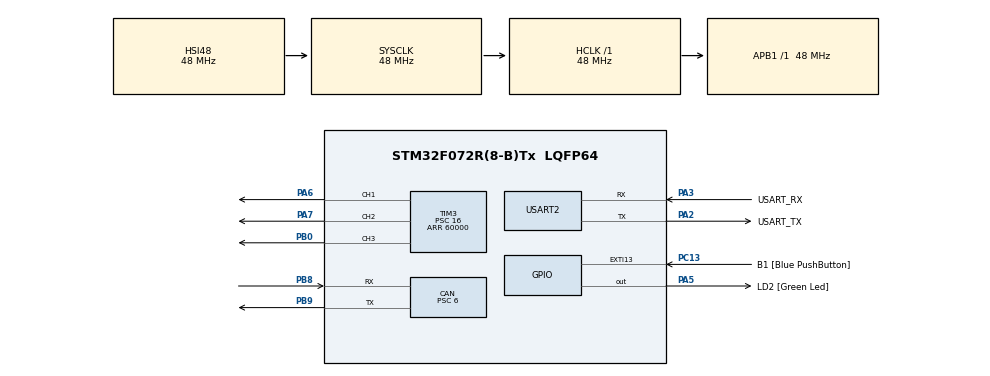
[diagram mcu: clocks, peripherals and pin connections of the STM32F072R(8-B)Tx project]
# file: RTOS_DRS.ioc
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CAN.ABOM=ENABLE
CAN.AWUM=ENABLE
CAN.BS1=CAN_BS1_6TQ
CAN.BS2=CAN_BS2_1TQ
CAN.CalculateTimeQuantum=125.0
CAN.Prescaler=6
FREERTOS.Tasks01=start_update_ca,24,128,start_update_calculate_wing_angle,Default,NULL,Dynamic,NULL,NULL;actuate_wings,24,128,start_actuate_wings,Default,NULL,Dynamic,NULL,NULL;DRS_button,24,128,start_DRS_button,Default,NULL,Dynamic,NULL,NULL;start_fetch_dat,24,128,start_fetch_data,Default,NULL,Dynamic,NULL,NULL
Mcu.Family=STM32F0
Mcu.Name=STM32F072R(8-B)Tx
Mcu.Package=LQFP64
NVIC.CEC_CAN_IRQn=true\:0\:0\:false\:false\:true\:true\:true\:true
NVIC.TIM6_DAC_IRQn=true\:0\:0\:false\:false\:true\:false\:false\:true
NVIC.TimeBase=TIM6_DAC_IRQn
NVIC.TimeBaseIP=TIM6
PA13.GPIO_Label=TMS
PA13.Mode=Serial_Wire
PA13.Signal=SYS_SWDIO
PA14.GPIO_Label=TCK
PA14.Mode=Serial_Wire
PA14.Signal=SYS_SWCLK
PA2.GPIO_Label=USART_TX
PA2.GPIO_Mode=GPIO_MODE_AF_PP
PA2.GPIO_PuPd=GPIO_NOPULL
PA2.GPIO_Speed=GPIO_SPEED_FREQ_LOW
PA2.Mode=Asynchronous
PA2.Signal=USART2_TX
PA3.GPIO_Label=USART_RX
PA3.GPIO_Mode=GPIO_MODE_AF_PP
PA3.GPIO_PuPd=GPIO_NOPULL
PA3.GPIO_Speed=GPIO_SPEED_FREQ_LOW
PA3.Mode=Asynchronous
PA3.Signal=USART2_RX
PA5.GPIO_Label=LD2 [Green Led]
PA5.GPIO_Mode=GPIO_MODE_OUTPUT_PP
PA5.GPIO_PuPd=GPIO_NOPULL
PA5.GPIO_Speed=GPIO_SPEED_FREQ_LOW
PA5.Signal=GPIO_Output
PA6.Signal=S_TIM3_CH1
PA7.Signal=S_TIM3_CH2
PB0.Signal=S_TIM3_CH3
PB8.Mode=Master
PB8.Signal=CAN_RX
PB9.Mode=Master
PB9.Signal=CAN_TX
PC13.GPIO_Label=B1 [Blue PushButton]
PC13.GPIO_ModeDefaultEXTI=GPIO_MODE_IT_FALLING
PC13.Signal=GPXTI13
PC14-OSC32_IN.Mode=LSE-External-Oscillator
PC14-OSC32_IN.Signal=RCC_OSC32_IN
PC15-OSC32_OUT.Mode=LSE-External-Oscillator
PC15-OSC32_OUT.Signal=RCC_OSC32_OUT
PF0-OSC_IN.Mode=HSE-External-Oscillator
PF0-OSC_IN.Signal=RCC_OSC_IN
PF1-OSC_OUT.Mode=HSE-External-Oscillator
PF1-OSC_OUT.Signal=RCC_OSC_OUT
ProjectManager.HeapSize=0x200
ProjectManager.StackSize=0x400
ProjectManager.TargetToolchain=STM32CubeIDE
RCC.AHBFreq_Value=48000000
RCC.APB1Freq_Value=48000000
RCC.APB1TimFreq_Value=48000000
RCC.FLatency-AdvancedSettings=FLASH_LATENCY_1
RCC.HCLKFreq_Value=48000000
RCC.PLLDivider=RCC_PREDIV_DIV2
RCC.PLLMUL=RCC_PLL_MUL12
RCC.PREFETCH_ENABLE-AdvancedSettings=1
RCC.SYSCLKFreq_VALUE=48000000
RCC.SYSCLKSource=RCC_SYSCLKSOURCE_HSI48
SH.S_TIM3_CH1.0=TIM3_CH1,PWM Generation1 CH1
SH.S_TIM3_CH2.0=TIM3_CH2,PWM Generation2 CH2
SH.S_TIM3_CH3.0=TIM3_CH3,PWM Generation3 CH3
TIM14.Prescaler=183
TIM3.Channel-PWM\ Generation1\ CH1=TIM_CHANNEL_1
TIM3.Channel-PWM\ Generation2\ CH2=TIM_CHANNEL_2
TIM3.Channel-PWM\ Generation3\ CH3=TIM_CHANNEL_3
TIM3.Period=60000
TIM3.Prescaler=16
USART2.VirtualMode=VM_ASYNC
USART2.VirtualMode-Asynchronous=VM_ASYNC
VP_FREERTOS_VS_CMSIS_V2.Mode=CMSIS_V2
VP_SYS_VS_tim6.Mode=TIM6
VP_TIM14_VS_ClockSourceINT.Mode=Enable_Timer
board=NUCLEO-F072RB

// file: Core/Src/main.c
/* USER CODE BEGIN Header */
/**
  ******************************************************************************
  * @file           : main.c
  * @brief          : Main program body
  ******************************************************************************
  * @attention
  *
  * <h2><center>&copy; Copyright (c) 2020 STMicroelectronics.
  * All rights reserved.</center></h2>
  *
  * This software component is licensed by ST under BSD 3-Clause license,
  * the "License"; You may not use this file except in compliance with the
  * License. You may obtain a copy of the License at:
  *                        opensource.org/licenses/BSD-3-Clause
  *
  ******************************************************************************
  */
/* USER CODE END Header */
#include "main.h"
#include "cmsis_os.h"

/* USER CODE BEGIN Includes */
#include "GO4_ACM_2020.h"
/* USER CODE END Includes */

CAN_HandleTypeDef hcan;

TIM_HandleTypeDef htim3;
TIM_HandleTypeDef htim14;

UART_HandleTypeDef huart2;

/* Definitions for start_update_ca */
osThreadId_t start_update_caHandle;
const osThreadAttr_t start_update_ca_attributes = {
  .name = "start_update_ca",
  .priority = (osPriority_t) osPriorityNormal,
  .stack_size = 128 * 4
};
/* Definitions for actuate_wings */
osThreadId_t actuate_wingsHandle;
const osThreadAttr_t actuate_wings_attributes = {
  .name = "actuate_wings",
  .priority = (osPriority_t) osPriorityNormal,
  .stack_size = 128 * 4
};
/* Definitions for DRS_button */
osThreadId_t DRS_buttonHandle;
const osThreadAttr_t DRS_button_attributes = {
  .name = "DRS_button",
  .priority = (osPriority_t) osPriorityNormal,
  .stack_size = 128 * 4
};
/* Definitions for start_fetch_dat */
osThreadId_t start_fetch_datHandle;
const osThreadAttr_t start_fetch_dat_attributes = {
  .name = "start_fetch_dat",
  .priority = (osPriority_t) osPriorityNormal,
  .stack_size = 128 * 4
};

void SystemClock_Config(void);
static void MX_GPIO_Init(void);
static void MX_USART2_UART_Init(void);
static void MX_TIM3_Init(void);
static void MX_CAN_Init(void);
static void MX_TIM14_Init(void);
void start_update_calculate_wing_angle(void *argument);
void start_actuate_wings(void *argument);
void start_DRS_button(void *argument);
void start_fetch_data(void *argument);

int main(void)
{

  /* MCU Configuration--------------------------------------------------------*/

  /* Reset of all peripherals, Initializes the Flash interface and the Systick. */
  HAL_Init();

  /* Configure the system clock */
  SystemClock_Config();

  /* Initialize all configured peripherals */
  MX_GPIO_Init();
  MX_USART2_UART_Init();
  MX_TIM3_Init();
  MX_CAN_Init();
  MX_TIM14_Init();
  /* USER CODE BEGIN 2 */
  /************** RUNNING CONFIG CALLS **************/

  ACM_Init();

  /* USER CODE END 2 */

  /* Init scheduler */
  osKernelInitialize();

  /* Create the thread(s) */
  /* creation of start_update_ca */
  start_update_caHandle = osThreadNew(start_update_calculate_wing_angle, NULL, &start_update_ca_attributes);

  /* creation of actuate_wings */
  actuate_wingsHandle = osThreadNew(start_actuate_wings, NULL, &actuate_wings_attributes);

  /* creation of DRS_button */
  DRS_buttonHandle = osThreadNew(start_DRS_button, NULL, &DRS_button_attributes);

  /* creation of start_fetch_dat */
  start_fetch_datHandle = osThreadNew(start_fetch_data, NULL, &start_fetch_dat_attributes);

  /* Start scheduler */
  osKernelStart();

  /* We should never get here as control is now taken by the scheduler */
  /* Infinite loop */
  while (1)
  {

  }
}

void SystemClock_Config(void)
{
  RCC_OscInitTypeDef RCC_OscInitStruct = {0};
  RCC_ClkInitTypeDef RCC_ClkInitStruct = {0};
  RCC_PeriphCLKInitTypeDef PeriphClkInit = {0};

  /** Initializes the RCC Oscillators according to the specified parameters
  * in the RCC_OscInitTypeDef structure.
  */
  RCC_OscInitStruct.OscillatorType = RCC_OSCILLATORTYPE_HSI48;
  RCC_OscInitStruct.HSI48State = RCC_HSI48_ON;
  RCC_OscInitStruct.PLL.PLLState = RCC_PLL_NONE;
  if (HAL_RCC_OscConfig(&RCC_OscInitStruct) != HAL_OK)
  {
    Error_Handler();
  }
  /** Initializes the CPU, AHB and APB buses clocks
  */
  RCC_ClkInitStruct.ClockType = RCC_CLOCKTYPE_HCLK|RCC_CLOCKTYPE_SYSCLK
                              |RCC_CLOCKTYPE_PCLK1;
  RCC_ClkInitStruct.SYSCLKSource = RCC_SYSCLKSOURCE_HSI48;
  RCC_ClkInitStruct.AHBCLKDivider = RCC_SYSCLK_DIV1;
  RCC_ClkInitStruct.APB1CLKDivider = RCC_HCLK_DIV1;

  if (HAL_RCC_ClockConfig(&RCC_ClkInitStruct, FLASH_LATENCY_1) != HAL_OK)
  {
    Error_Handler();
  }
  PeriphClkInit.PeriphClockSelection = RCC_PERIPHCLK_USART2;
  PeriphClkInit.Usart2ClockSelection = RCC_USART2CLKSOURCE_PCLK1;
  if (HAL_RCCEx_PeriphCLKConfig(&PeriphClkInit) != HAL_OK)
  {
    Error_Handler();
  }
}

static void MX_CAN_Init(void)
{

  hcan.Instance = CAN;
  hcan.Init.Prescaler = 6;
  hcan.Init.Mode = CAN_MODE_NORMAL;
  hcan.Init.SyncJumpWidth = CAN_SJW_1TQ;
  hcan.Init.TimeSeg1 = CAN_BS1_6TQ;
  hcan.Init.TimeSeg2 = CAN_BS2_1TQ;
  hcan.Init.TimeTriggeredMode = DISABLE;
  hcan.Init.AutoBusOff = ENABLE;
  hcan.Init.AutoWakeUp = ENABLE;
  hcan.Init.AutoRetransmission = DISABLE;
  hcan.Init.ReceiveFifoLocked = DISABLE;
  hcan.Init.TransmitFifoPriority = DISABLE;
  if (HAL_CAN_Init(&hcan) != HAL_OK)
  {
    Error_Handler();
  }

}

static void MX_TIM3_Init(void)
{

  TIM_MasterConfigTypeDef sMasterConfig = {0};
  TIM_OC_InitTypeDef sConfigOC = {0};

  htim3.Instance = TIM3;
  htim3.Init.Prescaler = 16;
  htim3.Init.CounterMode = TIM_COUNTERMODE_UP;
  htim3.Init.Period = 60000;
  htim3.Init.ClockDivision = TIM_CLOCKDIVISION_DIV1;
  htim3.Init.AutoReloadPreload = TIM_AUTORELOAD_PRELOAD_DISABLE;
  if (HAL_TIM_PWM_Init(&htim3) != HAL_OK)
  {
    Error_Handler();
  }
  sMasterConfig.MasterOutputTrigger = TIM_TRGO_RESET;
  sMasterConfig.MasterSlaveMode = TIM_MASTERSLAVEMODE_DISABLE;
  if (HAL_TIMEx_MasterConfigSynchronization(&htim3, &sMasterConfig) != HAL_OK)
  {
    Error_Handler();
  }
  sConfigOC.OCMode = TIM_OCMODE_PWM1;
  sConfigOC.Pulse = 0;
  sConfigOC.OCPolarity = TIM_OCPOLARITY_HIGH;
  sConfigOC.OCFastMode = TIM_OCFAST_DISABLE;
  if (HAL_TIM_PWM_ConfigChannel(&htim3, &sConfigOC, TIM_CHANNEL_1) != HAL_OK)
  {
    Error_Handler();
  }
  if (HAL_TIM_PWM_ConfigChannel(&htim3, &sConfigOC, TIM_CHANNEL_2) != HAL_OK)
  {
    Error_Handler();
  }
  if (HAL_TIM_PWM_ConfigChannel(&htim3, &sConfigOC, TIM_CHANNEL_3) != HAL_OK)
  {
    Error_Handler();
  }
  HAL_TIM_MspPostInit(&htim3);

}

static void MX_TIM14_Init(void)
{

  htim14.Instance = TIM14;
  htim14.Init.Prescaler = 183;
  htim14.Init.CounterMode = TIM_COUNTERMODE_UP;
  htim14.Init.Period = 65535;
  htim14.Init.ClockDivision = TIM_CLOCKDIVISION_DIV1;
  htim14.Init.AutoReloadPreload = TIM_AUTORELOAD_PRELOAD_DISABLE;
  if (HAL_TIM_Base_Init(&htim14) != HAL_OK)
  {
    Error_Handler();
  }

}

static void MX_USART2_UART_Init(void)
{

  huart2.Instance = USART2;
  huart2.Init.BaudRate = 38400;
  huart2.Init.WordLength = UART_WORDLENGTH_8B;
  huart2.Init.StopBits = UART_STOPBITS_1;
  huart2.Init.Parity = UART_PARITY_NONE;
  huart2.Init.Mode = UART_MODE_TX_RX;
  huart2.Init.HwFlowCtl = UART_HWCONTROL_NONE;
  huart2.Init.OverSampling = UART_OVERSAMPLING_16;
  huart2.Init.OneBitSampling = UART_ONE_BIT_SAMPLE_DISABLE;
  huart2.AdvancedInit.AdvFeatureInit = UART_ADVFEATURE_NO_INIT;
  if (HAL_UART_Init(&huart2) != HAL_OK)
  {
    Error_Handler();
  }

}

static void MX_GPIO_Init(void)
{
  GPIO_InitTypeDef GPIO_InitStruct = {0};

  /* GPIO Ports Clock Enable */
  __HAL_RCC_GPIOC_CLK_ENABLE();
  __HAL_RCC_GPIOF_CLK_ENABLE();
  __HAL_RCC_GPIOA_CLK_ENABLE();
  __HAL_RCC_GPIOB_CLK_ENABLE();

  /*Configure GPIO pin Output Level */
  HAL_GPIO_WritePin(LD2_GPIO_Port, LD2_Pin, GPIO_PIN_RESET);

  /*Configure GPIO pin : B1_Pin */
  GPIO_InitStruct.Pin = B1_Pin;
  GPIO_InitStruct.Mode = GPIO_MODE_IT_FALLING;
  GPIO_InitStruct.Pull = GPIO_NOPULL;
  HAL_GPIO_Init(B1_GPIO_Port, &GPIO_InitStruct);

  /*Configure GPIO pin : LD2_Pin */
  GPIO_InitStruct.Pin = LD2_Pin;
  GPIO_InitStruct.Mode = GPIO_MODE_OUTPUT_PP;
  GPIO_InitStruct.Pull = GPIO_NOPULL;
  GPIO_InitStruct.Speed = GPIO_SPEED_FREQ_LOW;
  HAL_GPIO_Init(LD2_GPIO_Port, &GPIO_InitStruct);

}

void start_update_calculate_wing_angle(void *argument)
{
  /* USER CODE BEGIN 5 */
  /* Infinite loop */
  for(;;)
  {
	  //update the data
	  update_data();

	  //Pick all of the necessary values that should be used for calculation
	  arbitrate_acceleration();
	  arbitrate_speed();
	  arbitrate_steering_angle();

	  calculate_wing_angle();

	  osDelay(1);
  }
  // In case something gets severely whacked
    osThreadTerminate(NULL);

  /* USER CODE END 5 */
}

void start_actuate_wings(void *argument)
{
  /* USER CODE BEGIN start_actuate_wings */
  /* Infinite loop */
  for(;;)
  {
	  // send information to the servos
	  output_angles();
	  osDelay(1);
  }
  /* USER CODE END start_actuate_wings */
}

void start_DRS_button(void *argument)
{
  /* USER CODE BEGIN start_DRS_button */
  /* Infinite loop */
  for(;;)
  {
	  get_btn_state();
	  osDelay(1);
  }
  /* USER CODE END start_DRS_button */
}

void start_fetch_data(void *argument)
{
  /* USER CODE BEGIN start_fetch_data */
  /* Infinite loop */
  for(;;)
  {
	  // Send for all data without interfering with calculations
	  fetch_data();

	  osDelay(1);
  }
  /* USER CODE END start_fetch_data */
}

void HAL_TIM_PeriodElapsedCallback(TIM_HandleTypeDef *htim)
{
  if (htim->Instance == TIM6) {
    HAL_IncTick();
  }
}

void Error_Handler(void)
{
}

/************************ (C) COPYRIGHT STMicroelectronics *****END OF FILE****/
